# CH32X315 register map
Vendor: WCH Ltd.; File version: 1.1
Registers are 32-bit, read-write, reset 0x0 unless marked. A register's access mark holds for its fields unless they carry their own. Offsets are from the block's base; [hi:lo] are bit positions; {n}, {i} and the like mark numbered series; 'fields as' and 'values as' point back to an identical list.

## USBSS — USB3.0 ultra-high speed host /device controller
Base 0x40038000
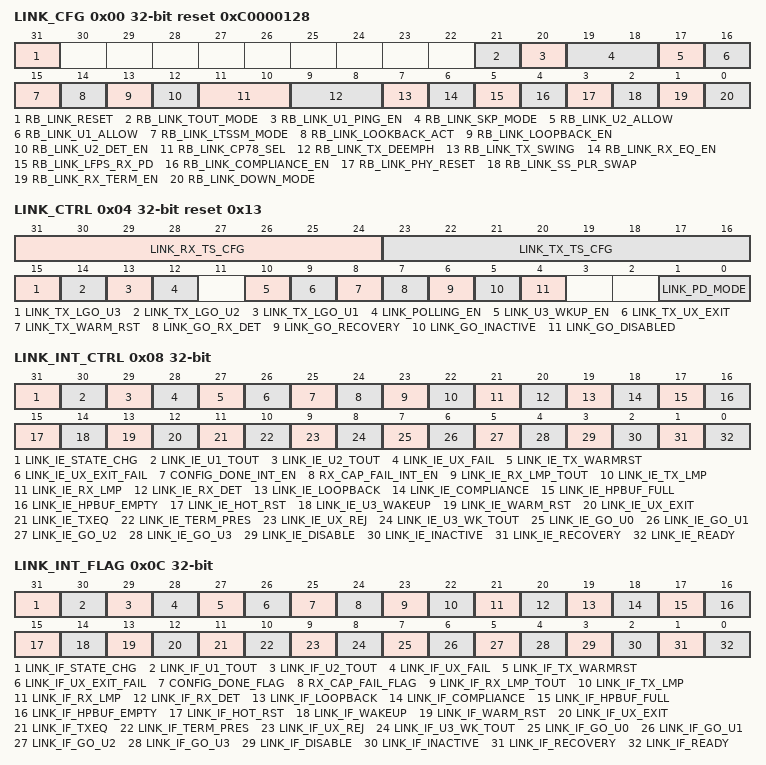
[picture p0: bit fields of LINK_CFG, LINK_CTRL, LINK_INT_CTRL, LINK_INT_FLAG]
0x00 LINK_CFG reset 0xC0000128 — LINK Configuration Register
  [31] RB_LINK_RESET — LINK reset, including the reset status machine and all interrupt flags, is highly effective.
  [21] RB_LINK_TOUT_MODE — protocol version
  [20] RB_LINK_U1_PING_EN — U1 sends PING_FPFS enable
  [19:18] RB_LINK_SKP_MODE — SKP rejection control for descrambling
  [17] RB_LINK_U2_ALLOW — High efficiency, after receiving the LGO_U2, the response LAU allows it to enter the U2 state, otherwise after receiving the LGO_U2, the response LXU refuses to enter the U2 state
  [16] RB_LINK_U1_ALLOW — High efficiency, after receiving the LGO_U1, the response LAU is allowed to enter the U1 state, otherwise the response LXU refuses to enter the U1 state after receiving the LGO_U1.
  [15] RB_LINK_LTSSM_MODE — The link state machine enters DISABLE mode
  [14] RB_LINK_LOOKBACK_ACT — Used in LOOPBACK mode for LOOPBACK host control pattern transmission (LOOPBACK slave holds 0), ACT is a high-level signal that lasts for a period of time
  [13] RB_LINK_LOOPBACK_EN — Allow to enter the LOOPBACK enable bit, high efficiency, use with the LOOKBACK enable in TX/RX_TS_CFG [3], both are valid, LINK can enter the LOOKBACK mode (used to enable the LOOPBACK slave data loop and error counting, the LOOPBACK host maintains 0).
  [12] RB_LINK_U2_DET_EN — Detection method of connected devices in U2 state
  [11:10] RB_LINK_CP78_SEL — In Compliance Pattern 7/8, send a length of consecutive 0 or consecutive 1
  [9:8] RB_LINK_TX_DEEMPH — Transmitter De-Emphasis control
  [7] RB_LINK_TX_SWING — Transmitter signal swing control, low swing power consumption, but affect the transmission distance
  [6] RB_LINK_RX_EQ_EN — Receiver equalization enables control, protocol specifics are optional
  [5] RB_LINK_LFPS_RX_PD — LFPS receive control, where the bit 1 indicates that LFPS receive is disabled.
  [4] RB_LINK_COMPLIANCE_EN — POLLING_LFPS whether the timeout enters COMPLIANCE mode
  [3] RB_LINK_PHY_RESET — PIPE Interface Reset
  [2] RB_LINK_SS_PLR_SWAP — Swap SSTX and SSRX polarity as follows
  [1] RB_LINK_RX_TERM_EN — Receiving terminal resistance control
  [0] RB_LINK_DOWN_MODE — Peripheral Type
0x04 LINK_CTRL access per field reset 0x13 — LINK Control Register
  [31:24] LINK_RX_TS_CFG ro — Received link control
  [23:16] LINK_TX_TS_CFG rw — Link Configuration for Sending TS1/TS2 Training Sequences
  [15] LINK_TX_LGO_U3 rw — After the bit is valid, it will be sent LGO_U3, high effectiveness, and the hardware will be automatically cleared
  [14] LINK_TX_LGO_U2 rw — After the bit is valid, it will send LGO_U2, high efficiency, and the hardware will be automatically cleared; If the other party responds with LXU, it indicates that it refuses to enter the U2 state; If the query LINK status is U2, it indicates that the other party accepts to enter the U2 low-power state, and the software should change the current power mode to P2.
  [13] LINK_TX_LGO_U1 rw — After the bit is valid, it will send LGO_U1, high efficiency, and the hardware will be automatically cleared. If the other party responds with LXU, it indicates that it refuses to enter U1 mode; If the query LINK status is U1, it indicates that the other party accepts to enter the U1 low-power state, and the software should change the current power mode to P1.
  [12] LINK_POLLING_EN rw — High validity, if the SS.RX_DETECT detects the TERM, the POLLING handshake will be performed after the software sets the bit to be valid.
  [10] LINK_U3_WKUP_EN rw — Receive U3 exti LPFS signal enable
  [9] LINK_TX_UX_EXIT rw — High efficiency, hardware automatic clearing
  [8] LINK_TX_WARM_RST rw — High effectiveness, cleared by software. This bit is valid and will send WARM_RESET. In device mode: After detecting that the host has continuously sent WARM_RESET for 18 ms, the device controller will automatically declare that it has detected WARM_RESET and reset it.
  [7] LINK_GO_RX_DET rw — Before setting this bit, the PD_MODE should be set to P2 mode, and the LINK should be set to enter the SS.RX_DETECT, and the software query TERM_PRESENT know whether there is a connection or whether the connection is disconnected. High effectiveness, automatic clearing.
  [6] LINK_GO_RECOVERY rw — Set the LINK to SS.RECOVERY, which is highly effective and the hardware is automatically cleared.
  [5] LINK_GO_INACTIVE rw — Set LINK to SS.INACTIVE, high efficiency, hardware automatic clearing.
  [4] LINK_GO_DISABLED rw — RW Set LINK to SS.DISABLED, which is highly effective and requires software to clear it. If the hardware automatically goes to SS.DIABLED, then the bit is automatically set to 1 by the hardware. In device mode, if the USB2.0 bus reset is received, the software should first set the PD_MODE to P2 mode, and then clear this bit, LTSSM will automatically enter the SS.RX_DETECT, the device will be detected 8 times (every 12ms), if no TERM is detected, it will enter the DISABLE state, and communicate in USB2.0 mode at the same time. In host mode, a BUS_RESET signal should be sent through the USB2.0 controller, the software should first set the PD_MODE to P2 mode, then clear this bit, and if a TERM is detected, a POLLING_LFPS handshake will be made. Otherwise, the software should set the power mode to P3 and communicate in USB2.0 mode.
  [1:0] LINK_PD_MODE rw — Configure the current power mode of the PHY, corresponding to PO/P1/P2/P3 in the PIPE
0x08 LINK_INT_CTRL — LINK Interrupt Enable Register
  [31] LINK_IE_STATE_CHG — Link state machine change flag interrupt enable
  [30] LINK_IE_U1_TOUT — U1 Timeout Interrupt Enable
  [29] LINK_IE_U2_TOUT — U2 timeout interrupt enable
  [28] LINK_IE_UX_FAIL — UX conversion failure interrupt enable
  [27] LINK_IE_TX_WARMRST — Send WARM_RESET end interrupt enable
  [26] LINK_IE_UX_EXIT_FAIL — Exit UX failure interrupt enable
  [25] CONFIG_DONE_INT_EN — Link receives or sends to PORT_Capability LMP interrupt enable
  [24] RX_CAP_FAIL_INT_EN — The CAP of the other party receiving the link cannot be combined with its own CAP to make an interrupt enable of the uplink and downlink ports
  [23] LINK_IE_RX_LMP_TOUT — Receive LMP timeout interrupt enable
  [22] LINK_IE_TX_LMP — Successfully entering U0, you can send HP packet interrupt enable
  [21] LINK_IE_RX_LMP — Receive a link command flag interrupt enable
  [20] LINK_IE_RX_DET — Link enters Rx.Detect state interrupt enabled
  [19] LINK_IE_LOOPBACK — Link enters loopback mode for testing and fault isolation interrupt enablement
  [18] LINK_IE_COMPLIANCE — Link entry compliance tests, interrupted with compatibility tests or physical layer conformance tests
  [17] LINK_IE_HPBUF_FULL — HP_BUF send FIFO full interrupt enable
  [16] LINK_IE_HPBUF_EMPTY — HP_BUF send FIFO null interrupt enable
  [15] LINK_IE_HOT_RST — HOT RESET, which uses the reset interrupt of the TS1/TS2 ordered set
  [14] LINK_IE_U3_WAKEUP — In the U3 state, receive the low-frequency periodic signal (LFPS) wake-up interrupt enable
  [13] LINK_IE_WARM_RST — Warm reset (unconnected) interrupt enable with LPFS
  [12] LINK_IE_UX_EXIT — Receiving a request to exit the UX interrupts the enable
  [11] LINK_IE_TXEQ — LINK into POLLING_RXEQ for receiver equalization training interrupt enablement
  [10] LINK_IE_TERM_PRES — LINK entry RX_DETECT to detect the impedance detection interruption of the trace segment of the remote receiver enables the following functions
  [9] LINK_IE_UX_REJ — Send LGO_ Ux, receive LXU interrupt enablement that refuses to enter the ux send
  [8] LINK_IE_U3_WK_TOUT — When requesting an exit U3 command timeout interrupt enabled
  [7] LINK_IE_GO_U0 — LINK in U0 interrupt enabled
  [6] LINK_IE_GO_U1 — LINK is in U1 interrupt enable
  [5] LINK_IE_GO_U2 — LINK is in 2 interrupt enable
  [4] LINK_IE_GO_U3 — LINK is in U3 interrupt enable
  [3] LINK_IE_DISABLE — LINK in DISABLED interrupt enable
  [2] LINK_IE_INACTIVE — LINK is in INACTIVE interrupt enable
  [1] LINK_IE_RECOVERY — Due to the error LINK in RECOVERY interrupt enable
  [0] LINK_IE_READY — LINK is initialized, including two ports before (Heade Sequence Number Advertisement) and (RX Headr Buffer Credit Advertisement) interrupt enabled
0x0C LINK_INT_FLAG — LINK Interrupt Flag Register
  [31] LINK_IF_STATE_CHG — LINK_RESET reset to 0 (write 1 clear)
  [30] LINK_IF_U1_TOUT — U1 timeout interrupt; (write 1 clear)
  [29] LINK_IF_U2_TOUT — U2 timeout interrupt; (write 1 clear)
  [28] LINK_IF_UX_FAIL — Failed to enter the UX interrupted; (write 1 clear)
  [27] LINK_IF_TX_WARMRST — Interruption at the end of the WARM_RESET send; (write 1 clear)
  [26] LINK_IF_UX_EXIT_FAIL — Exit UX fails to interrupt; (write 1 clear)
  [25] CONFIG_DONE_FLAG — The link receives or sends to PORT_Capability LMP interrupt (write 1 to zero)
  [24] RX_CAP_FAIL_FLAG — The CAP of the other party received by the link cannot be combined with its own CAP to form an interrupt at the uplink and downlink ports (write 1 to clear it)
  [23] LINK_IF_RX_LMP_TOUT — After LINK initialization is complete, the Port Capabilities/Configuration LMPs timeout (20us) interrupt flag is exchanged.
  [22] LINK_IF_TX_LMP — LINK initializes the interrupt flag, and the software configures to send Port Capabilities LMP for port capability switching.
  [21] LINK_IF_RX_LMP — Receiving LMP interrupt flags
  [20] LINK_IF_RX_DET — After entering the RX_DETECT state interrupt flag, this position 1, the software will set the PWR_MODE to P2, ready for RX_DETECT
  [19] LINK_IF_LOOPBACK — LINK enters the LOOPBACK state interrupt flag.
  [18] LINK_IF_COMPLIANCE — LINK enters the COMPLIANCE status interrupt flag.
  [17] LINK_IF_HPBUF_FULL — Header Packet buffer full interrupt flag.
  [16] LINK_IF_HPBUF_EMPTY — Header Packet buffer empty interrupt flag.
  [15] LINK_IF_HOT_RST — The device receives the HOT RESET interrupt flag
  [14] LINK_IF_WAKEUP — The power supply is in P3 mode and the LFPS signal interrupt flag is detected.
  [13] LINK_IF_WARM_RST — The WARM_RESET state change (valid-> invalid or invalid->valid) received by the device interrupted the flag.
  [12] LINK_IF_UX_EXIT — LINK receives the LFPS ready to exit U1/U2/U3 request interrupt flag, after this position 1, the software should set the PWR_MODE to P0, after setting the PWR_MODE to P0, the UX exit timer starts to time, after reaching U1_EXIT_TIMER, U2_EXIT_TIMER, U3_WAKE_TIMER, LINK exits the Ux state, Go to Recovery
  [11] LINK_IF_TXEQ — LINK enters TXEQ state outage flag: Indicates completion of the POLLING handshake and waits for the software to set the PWR_MODE to P0 in order to enter the TXEQ stage.
  [10] LINK_IF_TERM_PRES — TERM disconnected or connection interrupted flag detected.
  [9] LINK_IF_UX_REJ — LINK refuses to enter low power mode (U1/U2) interrupt flag.
  [8] LINK_IF_U3_WK_TOUT — Wake up timeout interrupt flag (10ms) from U3.
  [7-n] LINK_IF_GO_U{n} (n=0..3) — LINK enters the U{n} state interrupt flag.
  [3] LINK_IF_DISABLE — LINK to enter the SS.DISABLE state interrupt flag
  [2] LINK_IF_INACTIVE — LINK enters the SS.INACTIVE state interrupt flag
  [1] LINK_IF_RECOVERY — LINK enters the SS.RECOVERY status interrupt flag
  [0] LINK_IF_READY — LINK enters the U0 state and completes the LINK initialization interrupt flag.
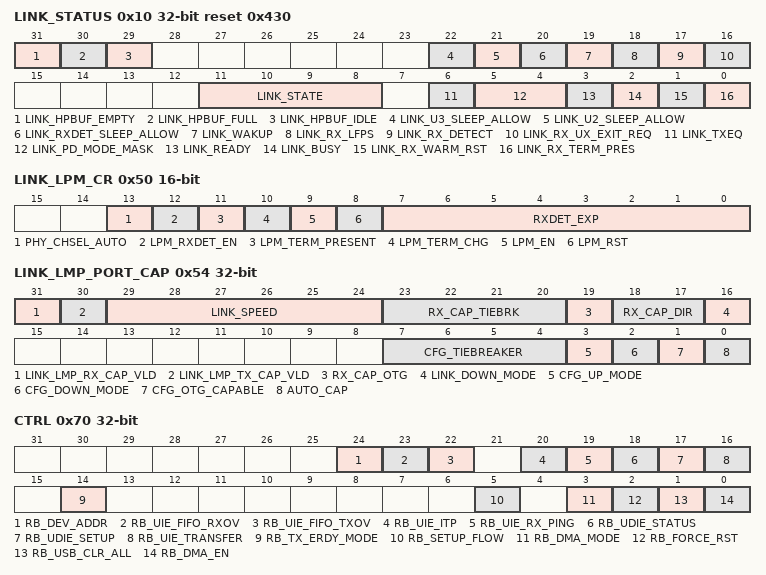
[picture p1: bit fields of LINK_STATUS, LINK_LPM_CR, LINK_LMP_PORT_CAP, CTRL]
0x10 LINK_STATUS ro reset 0x430
  [31] LINK_HPBUF_EMPTY — HP buffer is empty.
  [30] LINK_HPBUF_FULL — HP buffer is full.
  [29] LINK_HPBUF_IDLE — HP_BUF the status of sending FIFO IDLE
  [22] LINK_U3_SLEEP_ALLOW — The link is in the U3 state, allowing sleep.
  [21] LINK_U2_SLEEP_ALLOW — The link is in the U2 state, allowing sleep.
  [20] LINK_RXDET_SLEEP_ALLOW — The link is in the RXDET state, allowing sleep.
  [19] LINK_WAKUP — A link wake-up signal is received.
  [18] LINK_RX_LFPS — The link receives an LFPS signal.
  [17] LINK_RX_DETECT — The link is at P2 and is RX_DETECT underway.
  [16] LINK_RX_UX_EXIT_REQ — Received a request to exit the UX
  [11:8] LINK_STATE — Link Status
  [6] LINK_TXEQ — The link is in POLLING_RXEQ.
  [5:4] LINK_PD_MODE_MASK — Link Power Status
  [3] LINK_READY — When the LINK enters the U0 state, the position 1 will be automatically cleared after the initialization (broadcast) is completed, and the bit will be automatically cleared when it exits the U0 state.
  [2] LINK_BUSY — LINK busy state, the bit is 1 when the switching PD_MODE is completed, and the hardware will automatically clear it after the switching is completed.
  [1] LINK_RX_WARM_RST — Receive a valid WARM_RESET signal from the host (the hardware will automatically pull up after receiving the host's WARM_RESET 18ms).
  [0] LINK_RX_TERM_PRES — After RX_DETECT, if there is a receiver terminal resistor, the bit is 1.
0x17 LINK_ITP_PRE 8-bit ro reset 0x80 — LINK ITP timeout mode register
  [7:0] ITP_PRE — ITP Timeout Mode
0x1D LINK_U2_INACT_TIMER 8-bit — LINK U2 Inactivity Timeout Counter Threshold Register
  [7:0] U2_INACTIVE_TIMER — Values of the inactivity timeout counter threshold for U2
0x28 LINK_U1_WKUP_FILTER 8-bit reset 0x4A — U1 Wake Up LFPS Effective Time Register
  [7:0] U1_WKUP_FILTER — The effective duration of the LFPS received when U1 exits. When the receiving LFPS reaches this time, the received U1 EXIT can be considered valid, and the transmitted LFPS_LAST is raised, and the handshake is successful, which defaults to 600ns. U1_WKUP_FILTER [7]: the unit of time that controls U1_WKUP_FILTER [6:0]
0x2C LINK_U2_WKUP_FILTER 8-bit reset 0x2 — U2 Wake LFPS Effective Time Register
  [6:0] U2_WKUP_FILTER — When the received LFPS reaches this time, the transmitted LFPS_LAST is raised and the handshake is successful, and the received U2 EXIT is considered valid, the duration is (n)us, and the default is 2us.
0x30 LINK_U3_WKUP_FILTER 8-bit reset 0x64 — U3 Wake LFPS Effective Time Register
  [6:0] U3_WKUP_FILTER — When the received LFPS reaches this time, the transmitted LFPS_LAST is raised and the handshake is successful, and the received U3 EXIT is considered valid, the duration is (n)us, and the default is 100us.
0x40 LINK_ISO_DLY 16-bit reset 0x28 — LINK Synchronous Delay Register
  [15:0] LINK_ISOCH_DLY — The delay time for serial bit stream parsing to parallel data is 40ns by default, as the device writes the delay information to the register, which is invalid by 3 bits lower (because the clock frequency is 125MHz, the delay time needs to be set to 8*n).
0x50 LINK_LPM_CR 16-bit access per field — Link Power Management Registers
  [13] PHY_CHSEL_AUTO rw — The channel type of the PHY layer is automatically selected
  [12] LPM_RXDET_EN ro — When the LPM count reaches the desired value, it is confirmed that a device is connected to the PHY RXDET_EXP this bit is elevated.
  [11] LPM_TERM_PRESENT ro — The PHY layer detects the device connection.
  [10] LPM_TERM_CHG ro — The connected device changes, plugs in the device or unplugs the device.
  [9] LPM_EN rw — CLKLPM is fixed at 12MHz, when LINK_PD_MODE=3 and LPM_EN=0 and OSCOUTEN=0 and PLLALIV=0, CLKOSCO will stop and the crystal oscillator will stop
  [8] LPM_RST rw — Reset signal for LPM-related registers
  [7:0] RXDET_EXP rw — Detect external device counter registers.
0x54 LINK_LMP_PORT_CAP access per field — PORT_CAP Register
  [31] LINK_LMP_RX_CAP_VLD ro — Upon receipt of a valid PORT_CAP_LMP, the protocol stipulates that the two parties will exchange PORT_CAP_LMP within 20us after entering the U0 state
  [30] LINK_LMP_TX_CAP_VLD ro — PORT Capability configuration completion flag (software operation, write 1 clear 0)
  [29:24] LINK_SPEED ro — [24] Position 1, indicating that the supported device supports USB3.2 Gen1 (5Gbps).
  [23:20] RX_CAP_TIEBRK ro — Tiebreaker, used for PORT type quorum when two PORTs (REG_PORT_CAP[17:16]=11) with both uplink and downlink capabilities are connected, the port with the higher value becomes the downstream port, and if the tiebreakers of the two PORTs are equal, the PORT_CAP will be re-exchanged.
  [19] RX_CAP_OTG ro — OTG bits in LMP that receive Port Capability; Used for whether to go to this OTG function.
  [18:17] RX_CAP_DIR ro — [17]: If the position is 1, it means that the port can be configured as a downbound port; [18]: If the position is 1, it means that the port can be configured as an upbound port.
  [16] LINK_DOWN_MODE ro — Decide on your port configuration according to your and the other party's PORT Capability.
  [7:4] CFG_TIEBREAKER rw — Configure the Tiebreaker bit in the LMP of the Port Capability of this port; The higher the value, the lower exit.
  [3] CFG_UP_MODE rw — Configure the Direction bit in the LMP of the port capability of this port
  [2] CFG_DOWN_MODE rw — Configure the Direction low in the LMP of the port capability
  [1] CFG_OTG_CAPABLE rw — Configure the OTG bits in the LMP of the port capability of this port; Used for whether to go to this OTG function.
  [0] AUTO_CAP rw — When the automatic configuration of Port Capability fails, the bit is automatically cleared
0x58 LINK_LMP_RX_DATA0 ro — LMP Receive Data 0 Register
  [31:0] LINK_LMP_RX_DATA0 — After LMP reception is complete, HP data is stored in this register [31:0].
0x5C LINK_LMP_RX_DATA1 ro — LMP Receives Data 1 Register
  [31:0] LINK_LMP_RX_DATA1 — After LMP reception is complete, HP data is stored in this register [63:32].
0x60 LINK_LMP_RX_DATA2 ro — LMP Receives Data 2 Register
  [31:0] LINK_LMP_RX_DATA2 — After LMP reception is complete, HP data is stored in this register [95:64].
{0x64+4i} LINK_LMP_TX_DATA{i} (i=0..2) — USB Custom HP Data {i} Register
  [31:0] LINK_LMP_TX_DATA{i} — User-defined data sent to HP [{32i+31}:{32i}].
0x70 CTRL — Flash capecity register
  [24] RB_DEV_ADDR — The address of the USB device
  [23] RB_UIE_FIFO_RXOV — Receive FIFO overflow interrupt enable
  [22] RB_UIE_FIFO_TXOV — Sending FIFO Overflow Interrupt Enabled
  [20] RB_UIE_ITP — Send ITP to complete interrupt enable
  [19] RB_UIE_RX_PING — Receive PING-TP to complete the interrupt enablement
  [18] RB_UDIE_STATUS — Device mode: Receive STATUS transaction to complete interrupt enable
  [17] RB_UDIE_SETUP — Device mode: Receive SETUP transaction to complete interrupt enablement
  [16] RB_UIE_TRANSFER — USB transaction completion interrupt enabled
  [14] RB_TX_ERDY_MODE — Use in device mode
  [5] RB_SETUP_FLOW — SETUP Transaction Flow Control
  [3] RB_DMA_MODE — When performing burst DPH transmission, the operation of the next packet
  [2] RB_FORCE_RST — To reset the protocol layer and FIFO module, software clearing is required
  [1] RB_USB_CLR_ALL — Reset all software configuration registers, high efficiency, need software clearing
  [0] RB_DMA_EN — Enable DMA
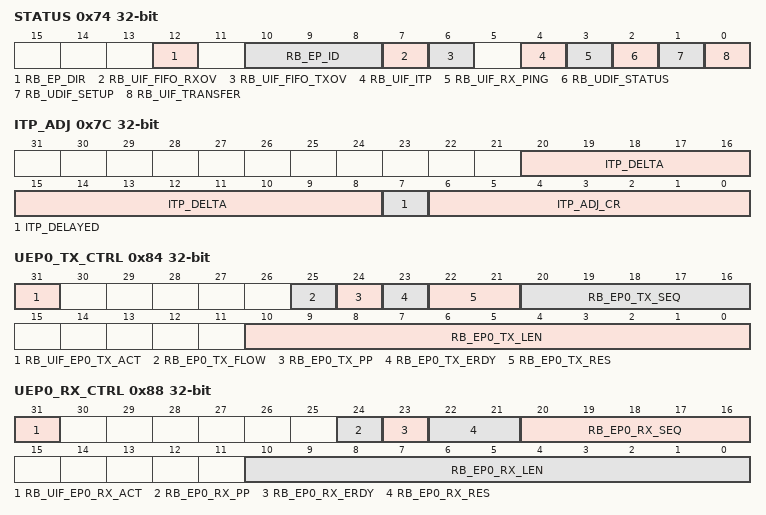
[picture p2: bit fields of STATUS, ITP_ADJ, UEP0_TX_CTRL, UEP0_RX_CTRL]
0x74 STATUS — USBSS Status Register
  [12] RB_EP_DIR — If the transmission and reception have an interrupt flag at the same time, the bit is 1, which prioritizes transmission (SETUP/STATUS independent interrupt)
  [10:8] RB_EP_ID — If multiple endpoints have an interrupt flag at the same time, the priority order is as follows (high-> low): Synchronous transmission > control transmission>block transmission/interrupted transmission, the smaller the endpoint number of the same endpoint type, the higher the priority.
  [7] RB_UIF_FIFO_RXOV — Receive FIFO overflow interrupt flag bits
  [6] RB_UIF_FIFO_TXOV — Send FIFO overflow interrupt flag bits
  [4] RB_UIF_ITP — Send ITP completion interrupt flag bit
  [3] RB_UIF_RX_PING — Receive PING-TP completion interrupt flag bit
  [2] RB_UDIF_STATUS — Device mode: Receives the STATUS transaction to complete the interrupt flag
  [1] RB_UDIF_SETUP — Device mode: Receives the SETUP transaction completion interrupt flag bit
  [0] RB_UIF_TRANSFER — USB transaction completion interrupt flag bit
0x78 ITP ro — The Interval register for the ITP package in USB
  [13:0] REG_ITP_INTERVAL — The Bus interval Counter field in the received ITP.
0x7C ITP_ADJ ro — Interval adaptive registers for ITP packets in USB
  [20:8] ITP_DELTA — The high 13bit (delta) of ITS in the ITP received in device mode represents the time difference from the start of the current ITP packet to the boundary of the previous bus interval.
  [7] ITP_DELAYED — In device mode, the delayed bit of the Link Control Word in the received ITP is 1 when the ITP is delayed.
  [6:0] ITP_ADJ_CR — In device mode, the Bus Interval Adjustment Control field in the received ITP.
0x80 UEP_TX_EN 16-bit — Endpoint Send Enable Register
  [15:1] RB_EP_TX_EN — Endpoint 1~15 Upload Enable
0x82 UEP_rX_EN 16-bit — Endpoint Receive Enable Register
  [15:1] RB_EP_RX_EN — Endpoint 1~15 downpass Enable
0x84 UEP0_TX_CTRL access per field — Endpoint 0 Transmit Control Register
  [31] RB_UIF_EP0_TX_ACT rw — The upload transaction is interrupted, the software writes 0 to clear zero, and the hardware sets it to 1.
  [25] RB_EP0_TX_FLOW ro — Flag to complete NRDY-TP send (answer)
  [24] RB_EP0_TX_PP ro — The PP bit in the received ACK-TP.
  [23] RB_EP0_TX_ERDY rw — The bit writes 1, sends ERDY, and the hardware of the bit is automatically cleared after the ERDY is sent.
  [22:21] RB_EP0_TX_RES rw — Response to ACK-TP
  [20:16] RB_EP0_TX_SEQ rw — The current sequence number of the endpoint is automatically cleared after receiving the SETUP transaction.
  [10:0] RB_EP0_TX_LEN rw — The endpoint sends length registers with a maximum value of 512B.
0x88 UEP0_RX_CTRL access per field — Endpoint 0 Receives Control Register
  [31] RB_UIF_EP0_RX_ACT rw — The downstream transaction completes the interrupt flag, the software writes 0 to clear zero, and the hardware sets it to 1
  [24] RB_EP0_RX_PP ro — The PP bit in the received DPH
  [23] RB_EP0_RX_ERDY rw — The bit writes 1, sends ERDY, and the hardware of the bit is automatically cleared after the ERDY is sent
  [22:21] RB_EP0_RX_RES rw — Response to DPH
  [20:16] RB_EP0_RX_SEQ rw — The serial number that the endpoint expects to receive
  [10:0] RB_EP0_RX_LEN ro — The endpoint receives the length register
0x8C R32_UH_TX_DMA_U3EP0_TX_DMA — Sending Buffer Address Register
  [31:0] U3EP0_TX_DMA — Endpoint 0 sends the buffer start address.
0x90 R32_UH_RX_DMA_U3EP0_RX_DMA — Receive Buffer Address Register
  [31:0] U3EP0_RX_DMA — Endpoint 0 receives the buffer start address.
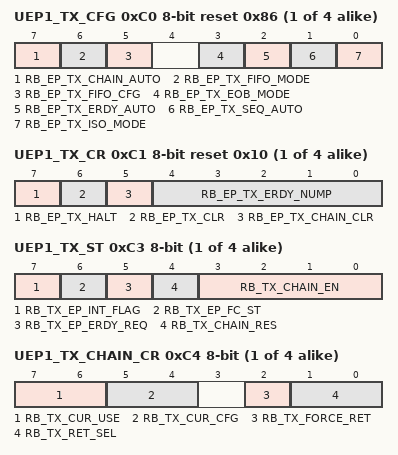
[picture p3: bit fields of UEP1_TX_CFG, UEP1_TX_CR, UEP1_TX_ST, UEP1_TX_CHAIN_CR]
{0xA0+0x20*i} UEP{i}_TX_CFG 8-bit reset 0x86 (i=1..4) — Endpoint {i} configures the registers
  [7] RB_EP_TX_CHAIN_AUTO — CHAIN automatically switches mode, this mode is recommended
  [6] RB_EP_TX_FIFO_MODE — A bit of 1 indicates that the current endpoint is using the FIFO mode, and the start and end addresses of the FIFO should be configured before the bit is 1
  [5] RB_EP_TX_FIFO_CFG — The object being operated on when the access offset address is 0xC~0xF
  [3] RB_EP_TX_EOB_MODE — If a short packet is sent, then EOB/LPF in ACK-TP
  [2] RB_EP_TX_ERDY_AUTO — ERDY automatic mode, the hardware will send ERDY, no software control required; The synchronous endpoint recommends clearing the bit
  [1] RB_EP_TX_SEQ_AUTO — Allow the software to write R16_EPn_ST->EP_SEQ_NUM
  [0] RB_EP_TX_ISO_MODE — 1 means that the current endpoint is a synchronous endpoint.
{0xA1+0x20*i} UEP{i}_TX_CR 8-bit reset 0x10 (i=1..4) — Endpoint {i} Control Register
  [7] RB_EP_TX_HALT — Endpoint stop, high efficiency, endpoint stop response STALL to DPH
  [6] RB_EP_TX_CLR — Write 1 to clear all configuration values and states of the endpoint, except for UEP_CFG
  [5] RB_EP_TX_CHAIN_CLR — Write 1 to clear all CHAIN configuration values and statuses.
  [4:0] RB_EP_TX_ERDY_NUMP — The hardware sends the NUMP field of ERDY-TP, and the general configuration value is the number of bursts supported. For example, if you support level 16 bursts, the field is configured to be 16.
{0xA2+0x20*i} UEP{i}_TX_SEQ 8-bit (i=1..4) — Endpoint {i} serial number register
  [4:0] RB_TX_EP_SEQ_NUM — The current serial number of the endpoint is writable in non-SEQ_AUTO mode and read-only in SEQ_AUTO mode
{0xA3+0x20*i} UEP{i}_TX_ST 8-bit access per field (i=1..4) — Endpoint {i} state register
  [7] RB_TX_EP_INT_FLAG ro — The endpoint is currently interrupted, the bit is read-only, and if all CHAIN_IF is 0, the bit is 0, otherwise it is 1.
  [6] RB_TX_EP_FC_ST rw — The endpoint is currently in the flow control state, write 1 to clear it
  [5] RB_TX_EP_ERDY_REQ rw — It indicates that it is currently in the sending ERDY; Writing 1 to that bit will send ERDY, used in non-ERDY_AUTO mode.
  [4] RB_TX_CHAIN_RES ro — CHAIN response state, corresponding to 4 independent CHAINs
  [3:0] RB_TX_CHAIN_EN ro — CHAIN enabled state, corresponding to 4 independent CHAINs
{0xA4+0x20*i} UEP{i}_TX_CHAIN_CR 8-bit access per field (i=1..4) — Endpoint {i} CHAIN control register
  [7:6] RB_TX_CUR_USE ro — The CHAIN serial number currently in use.
  [5:4] RB_TX_CUR_CFG ro — The currently configured CHAIN serial number.
  [2] RB_TX_FORCE_RET rw — This bit effectively forces the return of the selected CHAIN state machine configuration
  [1:0] RB_TX_RET_SEL rw — When the FORCE_RET is valid, this bit indicates the returned CHAIN state and configuration.
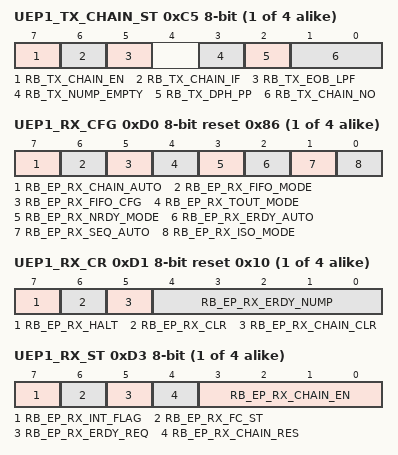
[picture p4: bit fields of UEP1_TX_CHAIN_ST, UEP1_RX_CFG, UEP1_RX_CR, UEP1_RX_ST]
{0xA5+0x20*i} UEP{i}_TX_CHAIN_ST 8-bit access per field (i=1..4) — Endpoint {i} CHAIN status register
  [7] RB_TX_CHAIN_EN ro — The currently used CHAIN enables the hardware to automatically set 1 after the UEP_CHAIN_NUMP register is configured, and the CHAIN is automatically cleared after the transmission is completed.
  [6] RB_TX_CHAIN_IF wo — The bit is only written, write 1 to release the current CHAIN_IF; The current CHAIN NUMP_EMPTY is 1 to cause this outage.
  [5] RB_TX_EOB_LPF rw — The EOB/LPF bits in the last pack of DPH of the current CHAIN
  [3] RB_TX_NUMP_EMPTY ro — If the NUMP in the current CHAIN is 0, then the position is 1
  [2] RB_TX_DPH_PP rw — The current status of the PP bit in the DPH.
  [1:0] RB_TX_CHAIN_NO rw — The CHAIN serial number that is currently generating the outage.
{0xA6+0x20*i} UEP{i}_TX_CHAIN_LEN 16-bit (i=1..4) — Endpoint {i} CHAIN sends the last packet length
  [10:0] CHAIN_TX_LEN — The CHAIN sends the length of the last packet.
0xC8 UEP1_TX_CHAIN_EXP_NUMP 8-bit — Number of NUMPs expected to be sent by endpoint 1
  [7:0] TX_CHAIN_EXP_NUMP — The number of DPP packets that can be sent by the CHAIN that has been completed.
0xC9 UEP1_TX_CHAIN_NUMP 8-bit — Number of NUMPs sent by endpoint 1
  [7:0] TX_CHAIN_NUMP — The number of DPP packets that have been transmitted; When the CHIN_EN is 0, the register is automatically cleared at the same time as the UEP_CHAIN_NUMP is written.
0xCA UEP1_TX_DMA_OFS 16-bit reset 0x400 — DMA offset length of endpoint 1
  [15:0] CHAIN_TX_DMA_OFS — The offset address of the DPP in the CHAIN.
0xCC UEP1_TX_DMA — DMA start address of endpoint 1
  [31:0] CHAIN_TX_DMA — In normal mode: The DMA start address of the CHAIN sending data. In FIFO mode: The FIFO start address is 16~23 bits of the mapping address in SRAM; The FIFO ends 16~23 bits of the mapped address in SRAM.
{0xB0+0x20*i} UEP{i}_RX_CFG 8-bit reset 0x86 (i=1..4) — Endpoint {i} Configuration Register
  [7] RB_EP_RX_CHAIN_AUTO — CHAIN automatically switches mode, this mode is recommended.
  [6] RB_EP_RX_FIFO_MODE — A bit of 1 indicates that the current endpoint is using the FIFO mode, and the start and end addresses of the FIFO should be configured before the bit is 1.
  [5] RB_EP_RX_FIFO_CFG — The object being operated on when the access offset address is 0xC~0xF
  [4] RB_EP_RX_TOUT_MODE — This bit is 1, and when the continuous burst packet is received, PP=1 and not a short packet, the DPH is not received after the timeout, resulting in TOUT_IF interrupt.
  [3] RB_EP_RX_NRDY_MODE — This bit is 1, and when a short packet or DPH (PP=0) is received, all CHAIN_EN are cleared, which will cause the DPH to respond to NRDY. Software reconfiguration required.
  [2] RB_EP_RX_ERDY_AUTO — ERDY automatic mode, the hardware will send ERDY, no software control required; The synchronous endpoint recommends clearing the bit.
  [1] RB_EP_RX_SEQ_AUTO — Allow the software to write R16_EPn_ST->EP_SEQ_NUM
  [0] RB_EP_RX_ISO_MODE — 1 means that the current endpoint is a synchronous endpoint
{0xB1+0x20*i} UEP{i}_RX_CR 8-bit reset 0x10 (i=1..4) — Endpoint {i} Control Register
  [7] RB_EP_RX_HALT — Endpoint stop, high efficiency, endpoint stop response STALL to DPH
  [6] RB_EP_RX_CLR — Write 1 to clear all configuration values and states of the endpoint, except for UEP_CFG
  [5] RB_EP_RX_CHAIN_CLR — Write 1 to clear all CHAIN configuration values and statuses.
  [4:0] RB_EP_RX_ERDY_NUMP — The hardware sends the NUMP field of ERDY-TP, and the general configuration value is the number of bursts supported. For example, if you support level 16 bursts, the field is configured to be 16.
{0xB2+0x20*i} UEP{i}_RX_SEQ 8-bit (i=1..4) — Endpoint {i} serial number register
  [4:0] RB_EP_RX_SEQ_NUM — The current serial number of the endpoint is writable in non-SEQ_AUTO mode and read-only in SEQ_AUTO mode
{0xB3+0x20*i} UEP{i}_RX_ST 8-bit access per field (i=1..4) — Endpoint {i} state register
  [7] RB_EP_RX_INT_FLAG ro — The endpoint is currently interrupted, the bit is read-only, and if all CHAIN_IF is 0, the bit is 0, otherwise it is 1.
  [6] RB_EP_RX_FC_ST rw — The endpoint is currently in the flow control state, write 1 to clear it
  [5] RB_EP_RX_ERDY_REQ rw — It indicates that it is currently in the sending ERDY; Writing 1 to that bit will send ERDY, used in non-ERDY_AUTO mode.
  [4] RB_EP_RX_CHAIN_RES ro — CHAIN response state, corresponding to 4 independent CHAINs
  [3:0] RB_EP_RX_CHAIN_EN ro — CHAIN enabled state, corresponding to 4 independent CHAINs
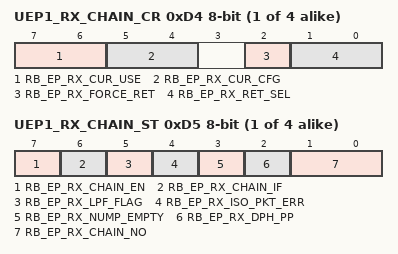
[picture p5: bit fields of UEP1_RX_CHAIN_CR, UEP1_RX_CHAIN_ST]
{0xB4+0x20*i} UEP{i}_RX_CHAIN_CR 8-bit access per field (i=1..4) — Endpoint {i} CHAIN control register
  [7:6] RB_EP_RX_CUR_USE ro — The CHAIN serial number currently in use.
  [5:4] RB_EP_RX_CUR_CFG ro — The currently configured CHAIN serial number.
  [2] RB_EP_RX_FORCE_RET rw — This bit effectively forces the return of the selected CHAIN state machine configuration
  [1:0] RB_EP_RX_RET_SEL rw — When the FORCE_RET is valid, this bit indicates the returned CHAIN state and configuration.
{0xB5+0x20*i} UEP{i}_RX_CHAIN_ST 8-bit access per field (i=1..4) — Endpoint {i} CHAIN status register
  [7] RB_EP_RX_CHAIN_EN ro — The currently used CHAIN enables the hardware to automatically set 1 after the UEP_CHAIN_NUMP register is configured, and the CHAIN is automatically cleared after the transmission is completed.
  [6] RB_EP_RX_CHAIN_IF rw — The bit is only written, write 1 to release the current CHAIN_IF; The interrupt occurs when any of the following conditions are met
  [5] RB_EP_RX_LPF_FLAG ro — Only the synchronous downhaul endpoint is used to receive the LPF status in the DPH currently received.
  [4] RB_EP_RX_ISO_PKT_ERR ro — Only the synchronous downhaul endpoint is used, and there is a CRC32 error in the currently receiving DPP
  [3] RB_EP_RX_NUMP_EMPTY ro — If the NUMP in the current CHAIN is 0, then the position is 1
  [2] RB_EP_RX_DPH_PP ro — The current status of the PP bit in the DPH.
  [1:0] RB_EP_RX_CHAIN_NO ro — The CHAIN serial number that is currently generating the outage.
0xD6 UEP1_RX_CHAIN_LEN 16-bit ro — The length of the last packet received by the endpoint 1 CHAIN
  [10:0] RB_EP_RX_CHAIN_RX_LEN — The currently completed CHAIN receives the length of the last package.
0xD8 UEP1_RX_CHAIN_MAX_NUMP 8-bit — Number of NUMPs that endpoint 1 can receive
  [7:0] RX_CHAIN_MAX_NUMP — The number of DPP packets that the CHAIN can receive.
0xD9 UEP1_RX_CHAIN_NUMP 8-bit ro — Number of NUMPs received by endpoint 1
  [7:0] TX_CHAIN_NUMP — The number of DPP packets that the CHAIN has received.
0xDA UEP1_RX_DMA_OFS 16-bit reset 0x400 — DMA offset length of endpoint 1
  [15:0] CHAIN_DMA_OFS — The offset address of the DPP in the CHAIN.
0xDC UEP1_RX_DMA — DMA start address of endpoint 1
  [31:0] CHAIN_DMA_BA — In normal mode: The DMA start address of the CHAIN receiving data. In FIFO mode: The FIFO start address is 16~23 bits of the mapping address in SRAM; The FIFO ends 16~23 bits of the mapped address in SRAM.
{0xA8+0x20*i} UEP{i}_TX_CHAIN_EXP_NUMP 8-bit (i=2..4) — Number of NUMPs expected to be sent by Endpoint {i}
  fields as UEP1_TX_CHAIN_EXP_NUMP
{0xA9+0x20*i} UEP{i}_TX_CHAIN_NUMP 8-bit (i=2..4) — Number of NUMPs sent by Endpoint {i}
  fields as UEP1_TX_CHAIN_NUMP
{0xAA+0x20*i} UEP{i}_TX_DMA_OFS 16-bit reset 0x400 (i=2..4) — DMA offset length of Endpoint {i}
  fields as UEP1_TX_DMA_OFS
{0xAC+0x20*i} UEP{i}_TX_DMA (i=2..4) — DMA start address of Endpoint {i}
  fields as UEP1_TX_DMA
{0xB6+0x20*i} UEP{i}_RX_CHAIN_LEN 16-bit ro (i=2..4) — The length of the last packet received by the Endpoint {i} CHAIN
  fields as UEP1_RX_CHAIN_LEN
{0xB8+0x20*i} UEP{i}_RX_CHAIN_MAX_NUMP 8-bit (i=2..4) — Number of NUMPs that Endpoint {i} can receive
  fields as UEP1_RX_CHAIN_MAX_NUMP
{0xB9+0x20*i} UEP{i}_RX_CHAIN_NUMP 8-bit ro (i=2..4) — Number of NUMPs received by Endpoint {i}
  fields as UEP1_RX_CHAIN_NUMP
{0xBA+0x20*i} UEP{i}_RX_DMA_OFS 16-bit reset 0x400 (i=2..4) — DMA offset length of Endpoint {i}
  [15:0] CHAIN_DMA_OFS — The offset address of the DPP in the CHAIN.
{0xBC+0x20*i} UEP{i}_RX_DMA (i=2..4) — DMA start address of Endpoint {i}
  fields as UEP1_RX_DMA
